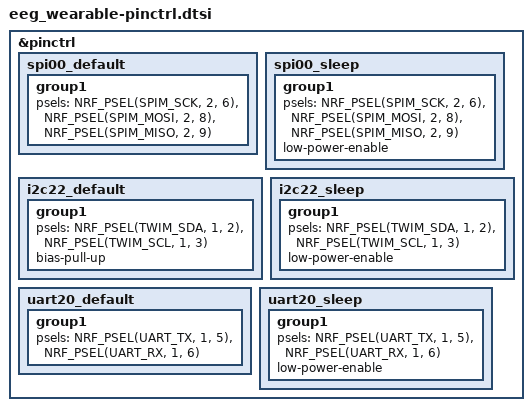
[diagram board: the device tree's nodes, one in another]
#include <dt-bindings/pinctrl/nrf-pinctrl.h>

&pinctrl {
    /* ADS1299 SPI — spi00 (fast domain, gpio2) */
    spi00_default: spi00_default {
        group1 {
            psels = <NRF_PSEL(SPIM_SCK,  2, 6)>,
                    <NRF_PSEL(SPIM_MOSI, 2, 8)>,
                    <NRF_PSEL(SPIM_MISO, 2, 9)>;
        };
    };
    spi00_sleep: spi00_sleep {
        group1 {
            psels = <NRF_PSEL(SPIM_SCK,  2, 6)>,
                    <NRF_PSEL(SPIM_MOSI, 2, 8)>,
                    <NRF_PSEL(SPIM_MISO, 2, 9)>;
            low-power-enable;
        };
    };

    /* IMU I2C — i2c22 (gpio1) */
    i2c22_default: i2c22_default {
        group1 {
            psels = <NRF_PSEL(TWIM_SDA, 1, 2)>,
                    <NRF_PSEL(TWIM_SCL, 1, 3)>;
            bias-pull-up; /* required for TWIM open-drain operation */
        };
    };
    i2c22_sleep: i2c22_sleep {
        group1 {
            psels = <NRF_PSEL(TWIM_SDA, 1, 2)>,
                    <NRF_PSEL(TWIM_SCL, 1, 3)>;
            low-power-enable;
        };
    };

    /* Debug UART — uart20 (gpio1) */
    uart20_default: uart20_default {
        group1 {
            psels = <NRF_PSEL(UART_TX, 1, 5)>,
                    <NRF_PSEL(UART_RX, 1, 6)>;
        };
    };
    uart20_sleep: uart20_sleep {
        group1 {
            psels = <NRF_PSEL(UART_TX, 1, 5)>,
                    <NRF_PSEL(UART_RX, 1, 6)>;
            low-power-enable;
        };
    };
};
